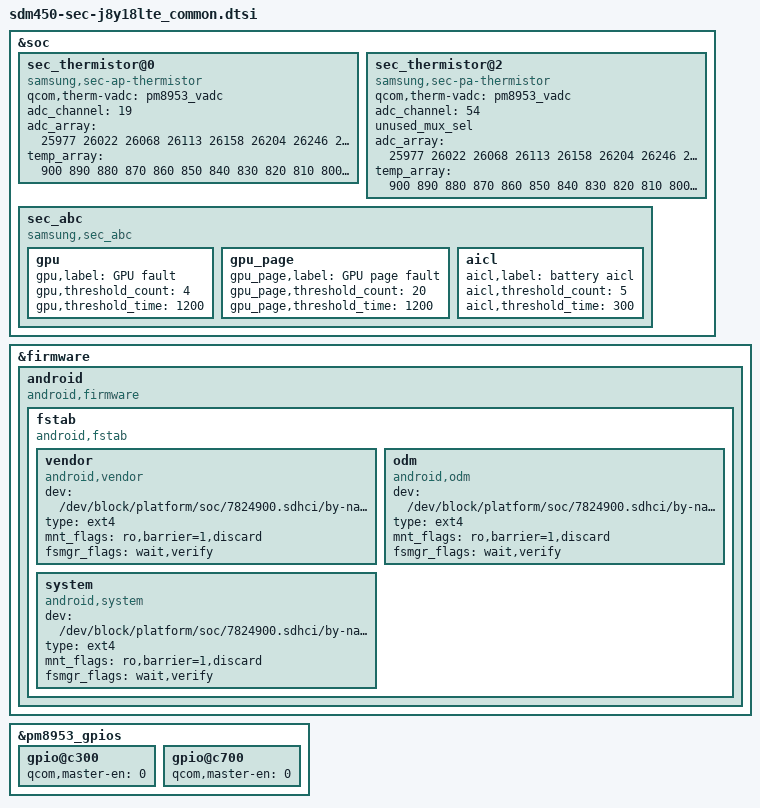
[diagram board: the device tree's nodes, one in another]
/*
 * Copyright (c) 2015-2017, The Linux Foundation. All rights reserved.
 *
 * This program is free software; you can redistribute it and/or modify
 * it under the terms of the GNU General Public License version 2 and
 * only version 2 as published by the Free Software Foundation.
 *
 * This program is distributed in the hope that it will be useful,
 * but WITHOUT ANY WARRANTY; without even the implied warranty of
 * MERCHANTABILITY or FITNESS FOR A PARTICULAR PURPOSE.  See the
 * GNU General Public License for more details.
 */

#include "../qcom/sdm450.dtsi"
#include "sdm450-sec-common.dtsi"
#include "sdm450-sec-j8y18lte_audio.dtsi"
#include "sdm450-sec-j8y18lte-input-common.dtsi"
#include "sdm450-sec-j8y18lte-battery-common.dtsi"

&soc {
	/* Thermistor table */
	sec_thermistor@0 {
		compatible = "samsung,sec-ap-thermistor";
		qcom,therm-vadc = <&pm8953_vadc>;
		status = "okay";
		adc_channel = <19>;
		adc_array = <25977 26022 26068 26113 26158 26204 26246 26289 26332 26375
					26418 26471 26524 26577 26630 26683 26749 26815 26881 26947
					27013 27106 27199 27291 27384 27477 27582 27687 27792 27897
					28002 28113 28224 28335 28446 28558 28674 28790 28906 29023
					29139 29294 29449 29603 29758 29913 30091 30269 30447 30625
					30803 30982 31162 31342 31522 31702 31888 32074 32260 32446
					32632 32829 33026 33224 33421 33618 33841 34064 34286 34509
					34732 34947 35162 35376 35591 35806 36012 36217 36423 36628
					36834 37010 37185 37361 37537 37713 37919 38126 38332 38539
					38745 38892 39038 39185 39331 39478 39628 39779 39930 40081
					40232 40324 40416 40508 40600 40692 40737 40782 40827 40872
					40917>;

		temp_array = <900 890 880 870 860 850 840 830 820 810
			800 790 780 770 760 750 740 730 720 710
			700 690 680 670 660 650 640 630 620 610
			600 590 580 570 560 550 540 530 520 510
			500 490 480 470 460 450 440 430 420 410
			400 390 380 370 360 350 340 330 320 310
			300 290 280 270 260 250 240 230 220 210
			200 190 180 170 160 150 140 130 120 110
			100 90 80 70 60 50 40 30 20 10
			0 (-10) (-20) (-30) (-40) (-50) (-60) (-70) (-80) (-90)
			(-100) (-110) (-120) (-130) (-140) (-150) (-160) (-170) (-180) (-190)
			(-200)>;
	};
	
	/* PA Thermistor table */
	sec_thermistor@2 {
		compatible = "samsung,sec-pa-thermistor";
		qcom,therm-vadc = <&pm8953_vadc>;
		status = "okay";
		adc_channel = <54>;
		unused_mux_sel;
		adc_array = <25977 26022 26068 26113 26158 26204 26246 26289 26332 26375
					26418 26471 26524 26577 26630 26683 26749 26815 26881 26947
					27013 27106 27199 27291 27384 27477 27582 27687 27792 27897
					28002 28113 28224 28335 28446 28558 28674 28790 28906 29023
					29139 29294 29449 29603 29758 29913 30091 30269 30447 30625
					30803 30982 31162 31342 31522 31702 31888 32074 32260 32446
					32632 32829 33026 33224 33421 33618 33841 34064 34286 34509
					34732 34947 35162 35376 35591 35806 36012 36217 36423 36628
					36834 37010 37185 37361 37537 37713 37919 38126 38332 38539
					38745 38892 39038 39185 39331 39478 39628 39779 39930 40081
					40232 40324 40416 40508 40600 40692 40737 40782 40827 40872
					40917>;

		temp_array = <900 890 880 870 860 850 840 830 820 810
			800 790 780 770 760 750 740 730 720 710
			700 690 680 670 660 650 640 630 620 610
			600 590 580 570 560 550 540 530 520 510
			500 490 480 470 460 450 440 430 420 410
			400 390 380 370 360 350 340 330 320 310
			300 290 280 270 260 250 240 230 220 210
			200 190 180 170 160 150 140 130 120 110
			100 90 80 70 60 50 40 30 20 10
			0 (-10) (-20) (-30) (-40) (-50) (-60) (-70) (-80) (-90)
			(-100) (-110) (-120) (-130) (-140) (-150) (-160) (-170) (-180) (-190)
			(-200)>;
	};

	sec_abc {
		compatible = "samsung,sec_abc";
		status = "okay";

		gpu {
			gpu,label="GPU fault";
			gpu,threshold_count=<4>;
			gpu,threshold_time=<1200>;
		};
		gpu_page {
			gpu_page,label="GPU page fault";
			gpu_page,threshold_count=<20>;
			gpu_page,threshold_time=<1200>;
		};
		aicl {
			aicl,label="battery aicl";
			aicl,threshold_count=<5>;
			aicl,threshold_time=<300>;
		};
	};
};

&firmware {

	android {
		compatible = "android,firmware";

		fstab {
			compatible = "android,fstab";

			vendor {
				compatible = "android,vendor";
				dev = "/dev/block/platform/soc/7824900.sdhci/by-name/vendor";
				type = "ext4";
				mnt_flags = "ro,barrier=1,discard";
				fsmgr_flags = "wait,verify";
				status = "ok";
			};

			odm {
				compatible = "android,odm";
				dev = "/dev/block/platform/soc/7824900.sdhci/by-name/odm";
				type = "ext4";
				mnt_flags = "ro,barrier=1,discard";
				fsmgr_flags = "wait,verify";
				status = "ok";
			};

			system {
				compatible = "android,system";
				dev = "/dev/block/platform/soc/7824900.sdhci/by-name/system";
				type = "ext4";
				mnt_flags = "ro,barrier=1,discard";
				fsmgr_flags = "wait,verify";
				status = "ok";
			};
		};
	};
};

&pm8953_gpios {
    /* GPIO 4 */
    gpio@c300 {
        qcom,master-en = <0>;
        status = "okay";
    };
    /* GPIO 8 */
    gpio@c700 {
        qcom,master-en = <0>;
        status = "okay";
    };
};

